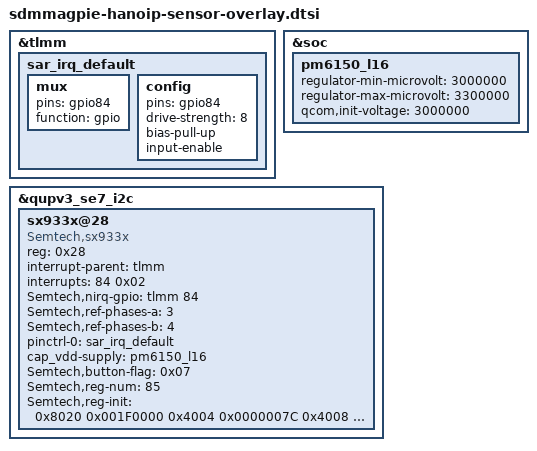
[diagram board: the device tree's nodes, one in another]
/* Copyright (c) 2018, The Linux Foundation. All rights reserved.
 *
 * This program is free software; you can redistribute it and/or modify
 * it under the terms of the GNU General Public License version 2 and
 * only version 2 as published by the Free Software Foundation.
 *
 * This program is distributed in the hope that it will be useful,
 * but WITHOUT ANY WARRANTY; without even the implied warranty of
 * MERCHANTABILITY or FITNESS FOR A PARTICULAR PURPOSE.  See the
 * GNU General Public License for more details.
 */
&tlmm {
	sar_irq_default: sar_irq_default {
		mux {
			pins = "gpio84";
			function = "gpio";
		};
		config {
			pins = "gpio84";
			drive-strength = <8>;
			bias-pull-up; /* PULL UP*/
			input-enable;
		};
	};
};

&soc {
	pm6150_l16 {
		regulator-min-microvolt = <3000000>;
		regulator-max-microvolt = <3300000>;
		qcom,init-voltage = <3000000>;
		status = "ok";
	};
};

&qupv3_se7_i2c {
	status = "ok";

	sx933x@28 {
		compatible = "Semtech,sx933x";
		reg = <0x28>;
		interrupt-parent = <&tlmm>;
		interrupts = <84 0x02>;
		Semtech,nirq-gpio = <&tlmm 84 0x02>;
		/*use PH3/4 as the reference sensor
		set it to 0xff if the ref-phases-x is not used*/
		Semtech,ref-phases-a = <3>;
		Semtech,ref-phases-b = <4>;
		pinctrl-names = "default";
                pinctrl-0 = <&sar_irq_default>;
		cap_vdd-supply = <&pm6150_l16>;
		Semtech,button-flag = <0x07>;
		Semtech,reg-num = <85>;
		Semtech,reg-init = <
		0x8020 0x001F0000
		0x4004 0x0000007C
		0x4008 0x00000000
		0x4054 0x00000400
		0x42C0 0x08000000
		0x42C4 0x0000003F
		0x800C 0x00000000
		0x8010 0x00000000
		0x8014 0x00000000
		0x8018 0x00000000
		0x801C 0x00000031
		0x8024 0x10000A6E
		0x8028 0x3FFE82E5
		0x802C 0x10000A6E
		0x8030 0x3DFF8268
		0x8034 0x10000A6E
		0x8038 0x2FFF8024
		0x803C 0x10000A6E
		0x8040 0x3FF78260
		0x8044 0x10000A6E
		0x8048 0x3FBF8024
		0x804C 0x0000088E
		0x8050 0x80001EE6
		0x8054 0x10223705
		0x8058 0x20630031
		0x805C 0x789C5000
		0x8060 0x00000000
		0x8064 0x006D0000
		0x8068 0x00000000
		0x806C 0x20002000
		0x8070 0x00010000
		0x8074 0x10223705
		0x8078 0x20630031
		0x807C 0x789C5000
		0x8080 0x00000000
		0x8084 0x006D0000
		0x8088 0x00000000
		0x808C 0x00200020
		0x8090 0x00020000
		0x8094 0x10222605
		0x8098 0x20630031
		0x809C 0x789C5000
		0x80A0 0x00000000
		0x80A4 0x004D0000
		0x80A8 0x00000000
		0x80AC 0x00200020
		0x80B0 0x00020000
		0x80B4 0x1052FF00
		0x80B8 0x20630031
		0x80BC 0x54AC5300
		0x80C0 0x00000000
		0x80C4 0x00000000
		0x80C8 0x00000000
		0x80CC 0x00000000
		0x80D0 0x00000000
		0x80D4 0x1052FF00
		0x80D8 0x20630031
		0x80DC 0x54AC5300
		0x80E0 0x00000000
		0x80E4 0x00000000
		0x80E8 0x00000000
		0x80EC 0x00000000
		0x80F0 0x00000000
		0x80F4 0x10162800
		0x80F8 0x20400031
		0x80FC 0x54AC5300
		0x8100 0x00000000
		0x8104 0x00000000
		0x8108 0x00000000
		0x810C 0x00000000
		0x8110 0x00000000
		0x8124 0x0400000B
		0x8128 0x0400000C
		0x812C 0x00000000
		0x8130 0x00000000
		0x8134 0x00000000
		0x8138 0x00000000
		0x813C 0x00000000
		0x8140 0x00000000
		0x8144 0x00000000
		0x8148 0x00000000
		0x814C 0x00000000
		0x81A4 0x01D00000
		0x8020 0x001F001F
		0x4280 0x0000000F
			>;

		status = "ok";
	};
};
